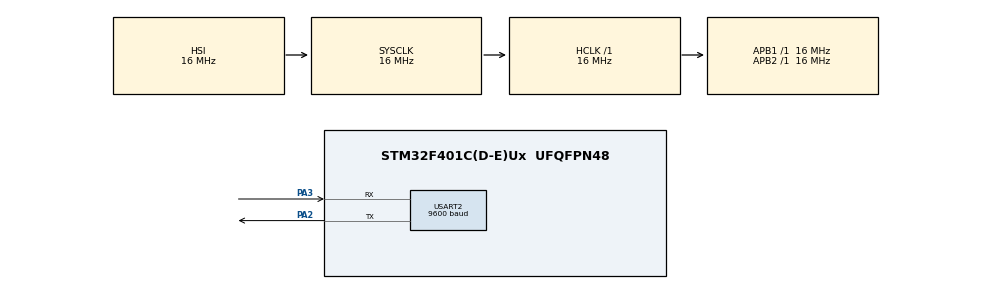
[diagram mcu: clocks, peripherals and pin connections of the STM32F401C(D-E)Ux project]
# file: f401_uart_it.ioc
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Mcu.Family=STM32F4
Mcu.Name=STM32F401C(D-E)Ux
Mcu.Package=UFQFPN48
NVIC.PriorityGroup=NVIC_PRIORITYGROUP_4
NVIC.USART2_IRQn=true\:0\:0\:false\:false\:true\:true\:true
PA13.Mode=Serial_Wire
PA13.Signal=SYS_JTMS-SWDIO
PA14.Mode=Serial_Wire
PA14.Signal=SYS_JTCK-SWCLK
PA2.Mode=Asynchronous
PA2.Signal=USART2_TX
PA3.Mode=Asynchronous
PA3.Signal=USART2_RX
ProjectManager.HeapSize=0x200
ProjectManager.StackSize=0x400
ProjectManager.TargetToolchain=STM32CubeIDE
RCC.AHBFreq_Value=16000000
RCC.APB1Freq_Value=16000000
RCC.APB2Freq_Value=16000000
RCC.CortexFreq_Value=16000000
RCC.HSE_VALUE=25000000
RCC.HSI_VALUE=16000000
RCC.LSE_VALUE=32768
RCC.SYSCLKFreq_VALUE=16000000
RCC.VCOOutputFreq_Value=192000000
USART2.BaudRate=9600
USART2.VirtualMode=VM_ASYNC
board=custom

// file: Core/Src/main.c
/* USER CODE BEGIN Header */
/**
  ******************************************************************************
  * @file           : main.c
  * @brief          : Main program body
  ******************************************************************************
  * @attention
  *
  * <h2><center>&copy; Copyright (c) 2023 STMicroelectronics.
  * All rights reserved.</center></h2>
  *
  * This software component is licensed by ST under BSD 3-Clause license,
  * the "License"; You may not use this file except in compliance with the
  * License. You may obtain a copy of the License at:
  *                        opensource.org/licenses/BSD-3-Clause
  *
  ******************************************************************************
  */
/* USER CODE END Header */
#include "main.h"

UART_HandleTypeDef huart2;

void SystemClock_Config(void);
static void MX_GPIO_Init(void);
static void MX_USART2_UART_Init(void);
/* USER CODE BEGIN PFP */
uint8_t rxBuff[5] = {};
uint8_t txBuff[] = "String send to UART";
/* USER CODE END PFP */

int main(void)
{

  /* MCU Configuration--------------------------------------------------------*/

  /* Reset of all peripherals, Initializes the Flash interface and the Systick. */
  HAL_Init();

  /* Configure the system clock */
  SystemClock_Config();

  /* Initialize all configured peripherals */
  MX_GPIO_Init();
  MX_USART2_UART_Init();
  /* USER CODE BEGIN 2 */
  HAL_UARTEx_ReceiveToIdle_IT(&huart2, rxBuff, sizeof(rxBuff));
  /* USER CODE END 2 */

  /* Infinite loop */
  while (1)
  {

  }
}

void SystemClock_Config(void)
{
  RCC_OscInitTypeDef RCC_OscInitStruct = {0};
  RCC_ClkInitTypeDef RCC_ClkInitStruct = {0};

  /** Configure the main internal regulator output voltage
  */
  __HAL_RCC_PWR_CLK_ENABLE();
  __HAL_PWR_VOLTAGESCALING_CONFIG(PWR_REGULATOR_VOLTAGE_SCALE2);
  /** Initializes the RCC Oscillators according to the specified parameters
  * in the RCC_OscInitTypeDef structure.
  */
  RCC_OscInitStruct.OscillatorType = RCC_OSCILLATORTYPE_HSI;
  RCC_OscInitStruct.HSIState = RCC_HSI_ON;
  RCC_OscInitStruct.HSICalibrationValue = RCC_HSICALIBRATION_DEFAULT;
  RCC_OscInitStruct.PLL.PLLState = RCC_PLL_NONE;
  if (HAL_RCC_OscConfig(&RCC_OscInitStruct) != HAL_OK)
  {
    Error_Handler();
  }
  /** Initializes the CPU, AHB and APB buses clocks
  */
  RCC_ClkInitStruct.ClockType = RCC_CLOCKTYPE_HCLK|RCC_CLOCKTYPE_SYSCLK
                              |RCC_CLOCKTYPE_PCLK1|RCC_CLOCKTYPE_PCLK2;
  RCC_ClkInitStruct.SYSCLKSource = RCC_SYSCLKSOURCE_HSI;
  RCC_ClkInitStruct.AHBCLKDivider = RCC_SYSCLK_DIV1;
  RCC_ClkInitStruct.APB1CLKDivider = RCC_HCLK_DIV1;
  RCC_ClkInitStruct.APB2CLKDivider = RCC_HCLK_DIV1;

  if (HAL_RCC_ClockConfig(&RCC_ClkInitStruct, FLASH_LATENCY_0) != HAL_OK)
  {
    Error_Handler();
  }
}

static void MX_USART2_UART_Init(void)
{

  huart2.Instance = USART2;
  huart2.Init.BaudRate = 9600;
  huart2.Init.WordLength = UART_WORDLENGTH_8B;
  huart2.Init.StopBits = UART_STOPBITS_1;
  huart2.Init.Parity = UART_PARITY_NONE;
  huart2.Init.Mode = UART_MODE_TX_RX;
  huart2.Init.HwFlowCtl = UART_HWCONTROL_NONE;
  huart2.Init.OverSampling = UART_OVERSAMPLING_16;
  if (HAL_UART_Init(&huart2) != HAL_OK)
  {
    Error_Handler();
  }

}

static void MX_GPIO_Init(void)
{

  /* GPIO Ports Clock Enable */
  __HAL_RCC_GPIOA_CLK_ENABLE();

}

/* USER CODE BEGIN 4 */

void HAL_UART_RxCpltCallback(UART_HandleTypeDef *huart)
{
  HAL_UARTEx_ReceiveToIdle_IT(&huart2, rxBuff, sizeof(rxBuff));
  HAL_UART_Transmit_IT(&huart2, txBuff, sizeof(txBuff));
}

/* USER CODE END 4 */

void Error_Handler(void)
{
  __disable_irq();
  while (1)
  {
  }
}

/************************ (C) COPYRIGHT STMicroelectronics *****END OF FILE****/
